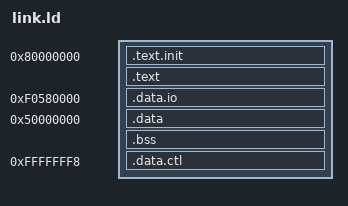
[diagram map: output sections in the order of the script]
/*
 NOTE NOTE NOTE NOTE NOTE NOTE NOTE NOTE NOTE NOTE NOTE NOTE NOTE NOTE NOTE NOTE
 This is an automatically generated file by pateln on Tue Sep 24 15:32:41 PDT 2024

 cmd:    veer -target=default --iccm_region=0x4 -set=ret_stack_size=8 -set=btb_enable=1 -set=btb_fullya=0 -set=btb_size=512 -set=bht_size=512 -set=div_bit=4 -set=div_new=1 -set=dccm_enable=1 -set=dccm_num_banks=4 -set=dccm_region=0x5 -set=dccm_offset=0x00000 -set=dccm_size=16 -set=dma_buf_depth=5 -set=fast_interrupt_redirect=1 -set=iccm_enable=0 -set=icache_enable=1 -set=icache_waypack=1 -set=icache_ecc=1 -set=icache_size=16 -set=icache_2banks=1 -set=icache_num_ways=2 -set=icache_bypass_enable=1 -set=icache_num_bypass=2 -set=icache_num_tag_bypass=2 -set=icache_tag_bypass_enable=1 -set=iccm_offset=0x0 -set=iccm_size=128 -set=iccm_num_banks=4 -set=lsu_stbuf_depth=4 -set=lsu_num_nbload=4 -set=load_to_use_plus1=0 -set=pic_2cycle=0 -set=pic_region=0x6 -set=pic_offset=0 -set=pic_size=32 -set=pic_total_int=31 -set=dma_buf_depth=5 -set=timer_legal_en=1 -set=bitmanip_zba=1 -set=bitmanip_zbb=1 -set=bitmanip_zbc=1 -set=bitmanip_zbe=0 -set=bitmanip_zbf=0 -set=bitmanip_zbp=0 -set=bitmanip_zbr=0 -set=bitmanip_zbs=1 -fpga_optimize=0 -snapshot=default 

*/
OUTPUT_ARCH( "riscv" )
ENTRY(_start)

SECTIONS
{
  . = 0x80000000;
  .text.init .  : { *(.text.init) }
  
  .text . : { *(.text) }
  _end = .;
  . = 0xf0580000;
  .data.io .  : { *(.data.io) }
    . = 0x50000000 ;
  .data  :  ALIGN(0x800) { *(.*data) *(.rodata*)}
  .bss :  {BSS_START = .; *(.*bss)}
  BSS_END = .;
  STACK = ALIGN(16) + 0x1000;
  
    . = 0xfffffff8; .data.ctl : { LONG(0x50000000); LONG(STACK) }
}

